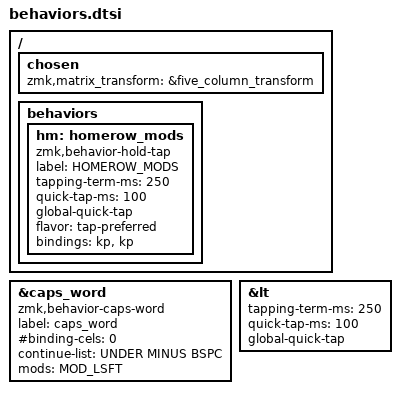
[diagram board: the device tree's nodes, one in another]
/ {
  chosen {
    zmk,matrix_transform = &five_column_transform;
  };
};

&caps_word {
  compatible = "zmk,behavior-caps-word";
  label = "caps_word";
  #binding-cels = <0>;
  continue-list = <UNDER MINUS BSPC>;
  mods = <MOD_LSFT>;
};

&lt {
  tapping-term-ms = <250>;
  quick-tap-ms = <100>;
  global-quick-tap;
};

/ {
  behaviors {
    hm: homerow_mods {
      compatible = "zmk,behavior-hold-tap";
      label = "HOMEROW_MODS";
      #binding-cells = <2>;
      tapping-term-ms = <250>;
      quick-tap-ms = <100>;
      global-quick-tap;
      flavor = "tap-preferred";
      bindings = <&kp>, <&kp>;
    };
  };
};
